# M5531 register map
File version: 1.0
Registers are 32-bit, read-write, reset 0x0 unless marked. A register's access mark holds for its fields unless they carry their own. Offsets are from the block's base; [hi:lo] are bit positions; 'fields as' and 'values as' point back to an identical list.

## HSUSBD (part 2 of 2) — USBD Register Map
Base 0x40205000
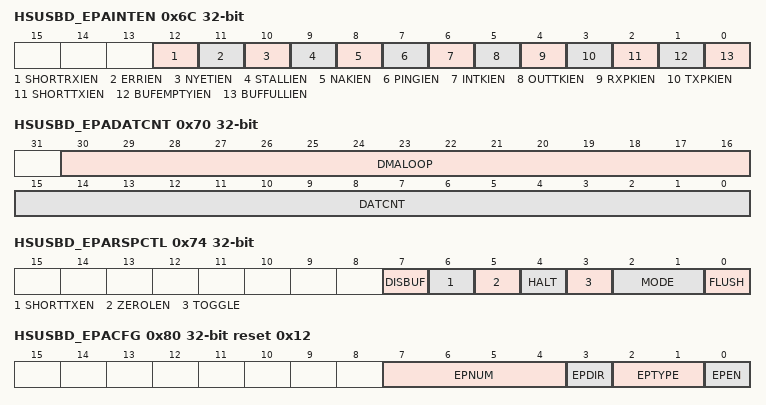
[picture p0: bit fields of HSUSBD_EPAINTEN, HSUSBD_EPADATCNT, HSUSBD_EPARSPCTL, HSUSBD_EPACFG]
0x6C HSUSBD_EPAINTEN — Endpoint A Interrupt Enable Control Register
  [12] SHORTRXIEN — Bulk Out Short Packet Received Interrupt Enable Bit. When set, this bit enables a local interrupt to be set whenever bulk out short packet occurs on the bus for this endpoint.
    0=Bulk out interrupt Disabled; 1=Bulk out interrupt Enabled
  [11] ERRIEN — ERR Sent Interrupt Enable Bit. When set, this bit enables a local interrupt to be set whenever ERR condition occurs on the bus for this endpoint.
    0=Error event interrupt Disabled; 1=Error event interrupt Enabled
  [10] NYETIEN — NYET Sent Interrupt Enable Bit. When set, this bit enables a local interrupt to be set whenever NYET condition occurs on the bus for this endpoint.
    0=NYET condition interrupt Disabled; 1=NYET condition interrupt Enabled
  [9] STALLIEN — USB STALL Sent Interrupt Enable Bit. When set, this bit enables a local interrupt to be set when a stall token is sent to the host.
    0=STALL token interrupt Disabled; 1=STALL token interrupt Enabled
  [8] NAKIEN — USB NAK Sent Interrupt Enable Bit. When set, this bit enables a local interrupt to be set when a NAK token is sent to the host.
    0=NAK token interrupt Disabled; 1=NAK token interrupt Enabled
  [7] PINGIEN — PING Token Interrupt Enable Bit. When set, this bit enables a local interrupt to be set when a PING token has been received from the host.
    0=PING token interrupt Disabled; 1=PING token interrupt Enabled
  [6] INTKIEN — Data IN Token Interrupt Enable Bit. When set, this bit enables a local interrupt to be set when a Data IN token has been received from the host.
    0=Data IN token interrupt Disabled; 1=Data IN token interrupt Enabled
  [5] OUTTKIEN — Data OUT Token Interrupt Enable Bit. When set, this bit enables a local interrupt to be set when a Data OUT token has been received from the host.
    0=Data OUT token interrupt Disabled; 1=Data OUT token interrupt Enabled
  [4] RXPKIEN — Data Packet Received Interrupt Enable Bit. When set, this bit enables a local interrupt to be set when a data packet has been received from the host.
    0=Data packet has been received from the host interrupt Disabled; 1=Data packet has been received from the host interrupt Enabled
  [3] TXPKIEN — Data Packet Transmitted Interrupt Enable Bit. When set, this bit enables a local interrupt to be set when a data packet has been transmitted to the host.
    0=Data packet has been transmitted to the host interrupt Disabled; 1=Data packet has been transmitted to the host interrupt Enabled
  [2] SHORTTXIEN — Short Packet Transferred Interrupt Enable Bit. When set, this bit enables a local interrupt to be set when a short data packet has been transferred to/from the host.
    0=Short data packet interrupt Disabled; 1=Short data packet interrupt Enabled
  [1] BUFEMPTYIEN — Buffer Empty Interrupt Enable Bit. When set, this bit enables a local interrupt to be set when a buffer empty condition is detected on the bus.
    0=Buffer empty interrupt Disabled; 1=Buffer empty interrupt Enabled
  [0] BUFFULLIEN — Buffer Full Interrupt Enable Bit. When set, this bit enables a local interrupt to be set when a buffer full condition is detected on the bus.
    0=Buffer full interrupt Disabled; 1=Buffer full interrupt Enabled
0x70 HSUSBD_EPADATCNT ro — Endpoint A Data Available Count Register
  [30:16] DMALOOP — DMA Loop. This register is the remaining DMA loop to complete. Each loop means 32-byte transfer.
  [15:0] DATCNT — Data Count. For an IN endpoint (EPDIR (HSUSBD_EPxCFG[3] is high.), this register returns the number of valid bytes in the IN endpoint packet buffer. For an OUT endpoint (EPDIR (HSUSBD_EPxCFG[3] is low.), this register returns the number of received valid bytes in the Host OUT transfer.
0x74 HSUSBD_EPARSPCTL — Endpoint A Response Control Register
  [7] DISBUF — Buffer Disable Bit. This bit is used to receive unknown size OUT short packet. The received packet size is reference HSUSBD_EPxDATCNT register.
    0=Buffer not disabled when Bulk-OUT short packet is received; 1=Buffer disabled when Bulk-OUT short packet is received
  [6] SHORTTXEN — Short Packet Transfer Enable. This bit is applicable only in case of Auto-Validate Method. This bit is set to validate any remaining data in the buffer which is not equal to the MPS of the endpoint, and happens to be the last transfer. This bit gets cleared once the data packet is sent.
    0=Not validate any remaining data in the buffer which is not equal to the MPS of the endpoint; 1=Validate any remaining data in the buffer which is not equal to the MPS of the endpoint
  [5] ZEROLEN — Zero Length. This bit is used to send a zero-length packet response to an IN-token. When this bit is set, a zero packet is sent to the host on reception of an IN-token. This bit gets cleared once the zero length data packet is sent.
    0=A zero packet is not sent to the host on reception of an IN-token; 1=A zero packet is sent to the host on reception of an IN-token
  [4] HALT — Endpoint Halt. This bit is used to send a STALL handshake as response to the token from the host. When an Endpoint Set Feature (ep_halt) is detected by the local CPU, it must write a '1' to this bit.
    0=Not send a STALL handshake as response to the token from the host; 1=Send a STALL handshake as response to the token from the host
  [3] TOGGLE — Endpoint Toggle. This bit is used to clear the endpoint data toggle bit. Reading this bit returns the current state of the endpoint data toggle bit. The local CPU may use this bit to initialize the end-point's toggle in case of reception of a Set Interface request or a Clear Feature (ep_halt) request from the host. Only when toggle bit is '1', this bit can be written into the inversed write data bit[3].
    0=Not clear the endpoint data toggle bit; 1=Clear the endpoint data toggle bit
  [2:1] MODE — Mode Control. The two bits decide the operation mode of the in-endpoint. These bits are not valid for an out-endpoint. The auto validate mode will be activated when the reserved mode is selected.
    0=Auto-Validate Mode; 1=Manual-Validate Mode; 2=Fly Mode
  [0] FLUSH — Buffer Flush. Writing 1 to this bit causes the packet buffer to be flushed and the corresponding EP_AVAIL register to be cleared. This bit is self-clearing. This bit should always be written after a configuration event.
    0=The packet buffer is not flushed; 1=The packet buffer is flushed by user
0x78 HSUSBD_EPAMPS — Endpoint A Maximum Packet Size Register
  [10:0] EPMPS — Endpoint Maximum Packet Size. This field determines the Maximum Packet Size of the Endpoint.
0x7C HSUSBD_EPATXCNT — Endpoint A Transfer Count Register
  [10:0] TXCNT — Endpoint Transfer Count. For IN endpoints, this field determines the total number of bytes to be sent to the host in case of manual validation method. For OUT endpoints, this field has no effect.
0x80 HSUSBD_EPACFG reset 0x12 — Endpoint A Configuration Register
  [7:4] EPNUM — Endpoint Number. This field selects the number of the endpoint. Valid numbers 1 to 15. Note: Do not support two endpoints have same endpoint number.
  [3] EPDIR — Endpoint Direction. Note: A maximum of one OUT and IN endpoint is allowed for each endpoint number.
    0=out-endpoint (Host OUT to Device); 1=in-endpoint (Host IN to Device)
  [2:1] EPTYPE — Endpoint Type. This field selects the type of this endpoint. Endpoint 0 is forced to a Control type.
    1=Bulk; 2=Interrupt; 3=Isochronous
  [0] EPEN — Endpoint Valid. When set, this bit enables this endpoint. This bit has no effect on Endpoint 0, which is always enabled.
    0=The endpoint Disabled; 1=The endpoint Enabled
0x84 HSUSBD_EPABUFSTART — Endpoint A RAM Start Address Register
  [13:0] SADDR — Endpoint Start Address. This is the start-address of the RAM space allocated for the endpoint A~R.
0x88 HSUSBD_EPABUFEND — Endpoint A RAM End Address Register
  [13:0] EADDR — Endpoint End Address. This is the end-address of the RAM space allocated for the endpoint A~R.
0x8C HSUSBD_EPBDAT — Endpoint B Data Register
  [31:0] EPDAT — Endpoint A~R Data Register. Endpoint A~R data buffer for the buffer transaction (read or write). Note: Only word or byte access are supported.
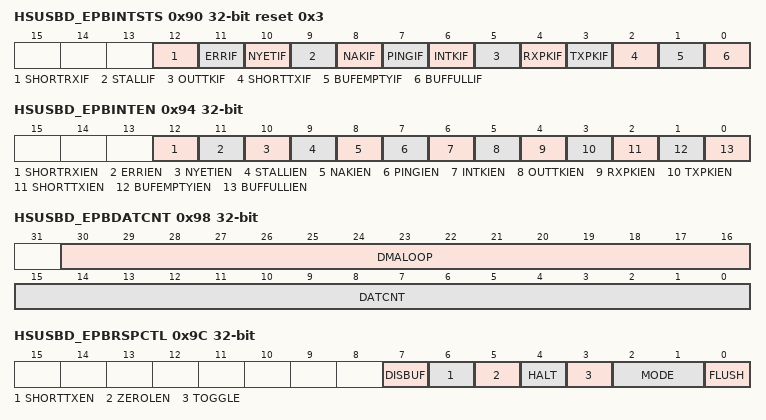
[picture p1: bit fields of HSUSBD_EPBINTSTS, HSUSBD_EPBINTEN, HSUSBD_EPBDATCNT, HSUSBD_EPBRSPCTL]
0x90 HSUSBD_EPBINTSTS reset 0x3 — Endpoint B Interrupt Status Register
  [12] SHORTRXIF — Bulk Out Short Packet Received Interrupt. Note: Write 1 to clear this bit to 0.
    0=No bulk out short packet is received; 1=Received bulk out short packet (including zero length packet)
  [11] ERRIF — ERR Sent Interrupt. Note: Write 1 to clear this bit to 0.
    0=No any error in the transaction; 1=There occurs any error in the transaction
  [10] NYETIF — NYET Sent Interrupt. Note: Write 1 to clear this bit to 0.
    0=The space available in the RAM is sufficient to accommodate the next on coming data packet; 1=The space available in the RAM is not sufficient to accommodate the next on coming data packet
  [9] STALLIF — USB STALL Sent Interrupt. Note: Write 1 to clear this bit to 0.
    0=The last USB packet could be accepted or provided because the endpoint was stalled, and was acknowledged with a STALL; 1=The last USB packet could not be accepted or provided because the endpoint was stalled, and was acknowledged with a STALL
  [8] NAKIF — USB NAK Sent Interrupt. Note: Write 1 to clear this bit to 0.
    0=The last USB IN packet could be provided, and was acknowledged with an ACK; 1=The last USB IN packet could not be provided, and was acknowledged with a NAK
  [7] PINGIF — PING Token Interrupt. Note: Write 1 to clear this bit to 0.
    0=A Data PING token has not been received from the host; 1=A Data PING token has been received from the host
  [6] INTKIF — Data IN Token Interrupt. Note: Write 1 to clear this bit to 0.
    0=Not Data IN token has been received from the host; 1=A Data IN token has been received from the host
  [5] OUTTKIF — Data OUT Token Interrupt. Note: Write 1 to clear this bit to 0.
    0=A Data OUT token has not been received from the host; 1=A Data OUT token has been received from the host. This bit also set by PING token (in high-speed only)
  [4] RXPKIF — Data Packet Received Interrupt. Note: Write 1 to clear this bit to 0.
    0=No data packet is received from the host by the endpoint; 1=A data packet is received from the host by the endpoint
  [3] TXPKIF — Data Packet Transmitted Interrupt. Note: Write 1 to clear this bit to 0.
    0=Not a data packet is transmitted from the endpoint to the host; 1=A data packet is transmitted from the endpoint to the host
  [2] SHORTTXIF — Short Packet Transferred Interrupt. Note: Write 1 to clear this bit to 0.
    0=The length of the last packet was not less than the Maximum Packet Size (EPMPS); 1=The length of the last packet was less than the Maximum Packet Size (EPMPS)
  [1] BUFEMPTYIF — Buffer Empty Interrupt. For an IN endpoint, a buffer is available to the local side for writing up to FIFO full of bytes. Note: This bit is read-only.
    0=The endpoint buffer is not empty. The currently selected buffer has not a count of 0; 1=The endpoint buffer is empty. The currently selected buffer has a count of 0, or no buffer is available on the local side (nothing to read)
  [0] BUFFULLIF — Buffer Full Interrupt. For an IN endpoint, the currently selected buffer is full, or no buffer is available to the local side for writing (no space to write). For an OUT endpoint, there is a buffer available on the local side, and there are FIFO full of bytes available to be read (entire packet is available for reading). Note: This bit is read-only.
    0=The endpoint packet buffer is not full; 1=The endpoint packet buffer is full
0x94 HSUSBD_EPBINTEN — Endpoint B Interrupt Enable Control Register
  fields as HSUSBD_EPAINTEN
0x98 HSUSBD_EPBDATCNT ro — Endpoint B Data Available Count Register
  fields as HSUSBD_EPADATCNT
0x9C HSUSBD_EPBRSPCTL — Endpoint B Response Control Register
  fields as HSUSBD_EPARSPCTL
0xA0 HSUSBD_EPBMPS — Endpoint B Maximum Packet Size Register
  fields as HSUSBD_EPAMPS
0xA4 HSUSBD_EPBTXCNT — Endpoint B Transfer Count Register
  fields as HSUSBD_EPATXCNT
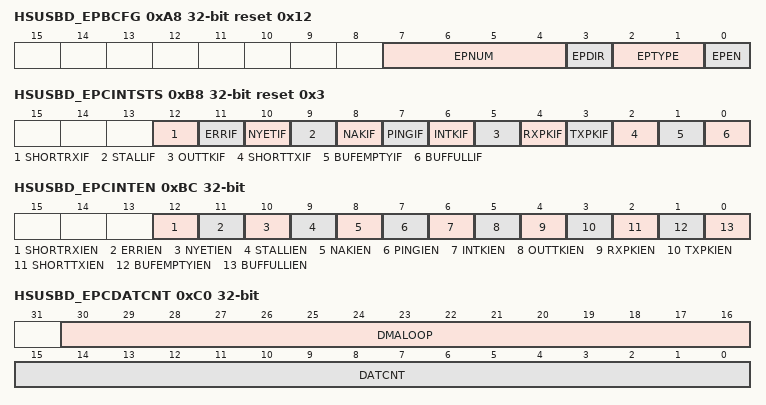
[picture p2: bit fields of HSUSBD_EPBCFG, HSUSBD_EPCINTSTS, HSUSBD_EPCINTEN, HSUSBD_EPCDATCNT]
0xA8 HSUSBD_EPBCFG reset 0x12 — Endpoint B Configuration Register
  fields as HSUSBD_EPACFG
0xAC HSUSBD_EPBBUFSTART — Endpoint B RAM Start Address Register
  fields as HSUSBD_EPABUFSTART
0xB0 HSUSBD_EPBBUFEND — Endpoint B RAM End Address Register
  fields as HSUSBD_EPABUFEND
0xB4 HSUSBD_EPCDAT — Endpoint C Data Register
  fields as HSUSBD_EPBDAT
0xB8 HSUSBD_EPCINTSTS reset 0x3 — Endpoint C Interrupt Status Register
  fields as HSUSBD_EPBINTSTS
0xBC HSUSBD_EPCINTEN — Endpoint C Interrupt Enable Control Register
  fields as HSUSBD_EPAINTEN
0xC0 HSUSBD_EPCDATCNT ro — Endpoint C Data Available Count Register
  fields as HSUSBD_EPADATCNT
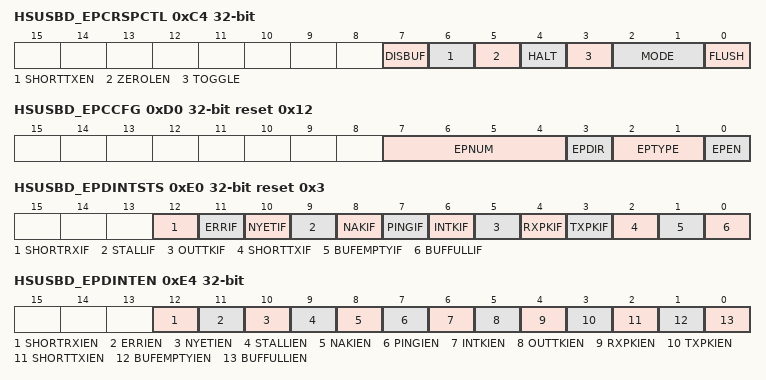
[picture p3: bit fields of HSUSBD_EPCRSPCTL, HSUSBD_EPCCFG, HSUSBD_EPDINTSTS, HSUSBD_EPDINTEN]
0xC4 HSUSBD_EPCRSPCTL — Endpoint C Response Control Register
  fields as HSUSBD_EPARSPCTL
0xC8 HSUSBD_EPCMPS — Endpoint C Maximum Packet Size Register
  fields as HSUSBD_EPAMPS
0xCC HSUSBD_EPCTXCNT — Endpoint C Transfer Count Register
  fields as HSUSBD_EPATXCNT
0xD0 HSUSBD_EPCCFG reset 0x12 — Endpoint C Configuration Register
  fields as HSUSBD_EPACFG
0xD4 HSUSBD_EPCBUFSTART — Endpoint C RAM Start Address Register
  fields as HSUSBD_EPABUFSTART
0xD8 HSUSBD_EPCBUFEND — Endpoint C RAM End Address Register
  fields as HSUSBD_EPABUFEND
0xDC HSUSBD_EPDDAT — Endpoint D Data Register
  fields as HSUSBD_EPBDAT
0xE0 HSUSBD_EPDINTSTS reset 0x3 — Endpoint D Interrupt Status Register
  fields as HSUSBD_EPBINTSTS
0xE4 HSUSBD_EPDINTEN — Endpoint D Interrupt Enable Control Register
  fields as HSUSBD_EPAINTEN
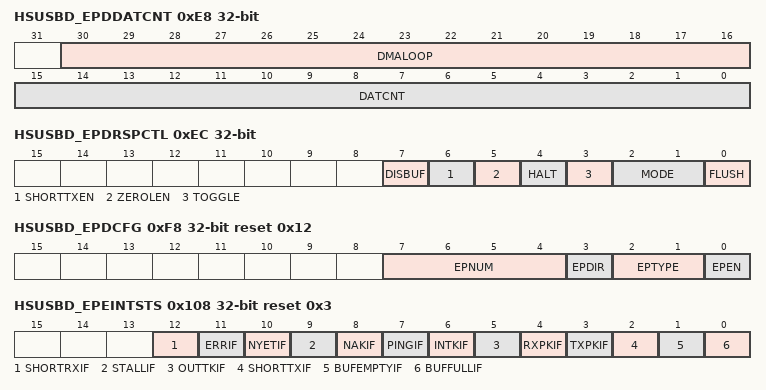
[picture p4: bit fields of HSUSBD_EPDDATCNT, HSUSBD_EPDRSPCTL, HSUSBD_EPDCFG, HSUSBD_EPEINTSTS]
0xE8 HSUSBD_EPDDATCNT ro — Endpoint D Data Available Count Register
  fields as HSUSBD_EPADATCNT
0xEC HSUSBD_EPDRSPCTL — Endpoint D Response Control Register
  fields as HSUSBD_EPARSPCTL
0xF0 HSUSBD_EPDMPS — Endpoint D Maximum Packet Size Register
  fields as HSUSBD_EPAMPS
0xF4 HSUSBD_EPDTXCNT — Endpoint D Transfer Count Register
  fields as HSUSBD_EPATXCNT
0xF8 HSUSBD_EPDCFG reset 0x12 — Endpoint D Configuration Register
  fields as HSUSBD_EPACFG
0xFC HSUSBD_EPDBUFSTART — Endpoint D RAM Start Address Register
  fields as HSUSBD_EPABUFSTART
0x100 HSUSBD_EPDBUFEND — Endpoint D RAM End Address Register
  fields as HSUSBD_EPABUFEND
0x104 HSUSBD_EPEDAT — Endpoint E Data Register
  fields as HSUSBD_EPBDAT
0x108 HSUSBD_EPEINTSTS reset 0x3 — Endpoint E Interrupt Status Register
  fields as HSUSBD_EPBINTSTS
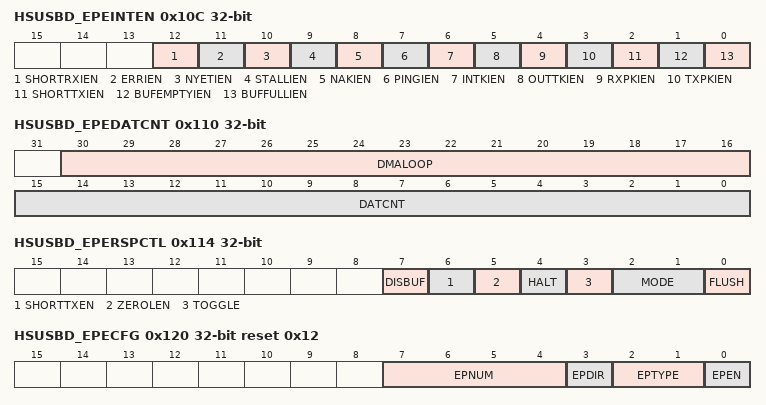
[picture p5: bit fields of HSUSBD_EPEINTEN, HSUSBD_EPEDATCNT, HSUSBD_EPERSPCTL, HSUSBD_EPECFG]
0x10C HSUSBD_EPEINTEN — Endpoint E Interrupt Enable Control Register
  fields as HSUSBD_EPAINTEN
0x110 HSUSBD_EPEDATCNT ro — Endpoint E Data Available Count Register
  fields as HSUSBD_EPADATCNT
0x114 HSUSBD_EPERSPCTL — Endpoint E Response Control Register
  fields as HSUSBD_EPARSPCTL
0x118 HSUSBD_EPEMPS — Endpoint E Maximum Packet Size Register
  fields as HSUSBD_EPAMPS
0x11C HSUSBD_EPETXCNT — Endpoint E Transfer Count Register
  fields as HSUSBD_EPATXCNT
0x120 HSUSBD_EPECFG reset 0x12 — Endpoint E Configuration Register
  fields as HSUSBD_EPACFG
0x124 HSUSBD_EPEBUFSTART — Endpoint E RAM Start Address Register
  fields as HSUSBD_EPABUFSTART
0x128 HSUSBD_EPEBUFEND — Endpoint E RAM End Address Register
  fields as HSUSBD_EPABUFEND
0x12C HSUSBD_EPFDAT — Endpoint F Data Register
  fields as HSUSBD_EPBDAT
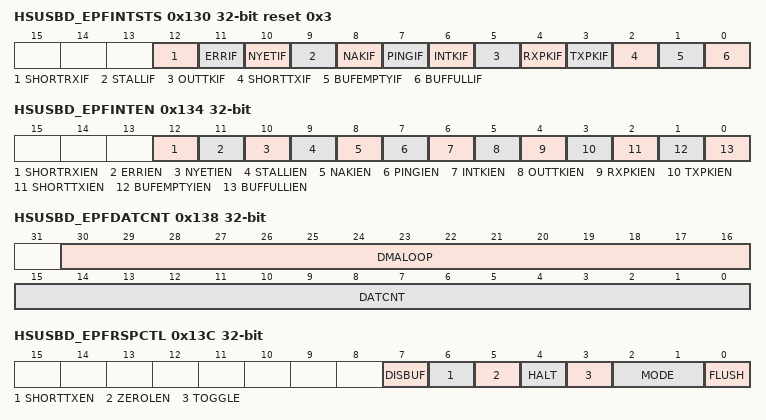
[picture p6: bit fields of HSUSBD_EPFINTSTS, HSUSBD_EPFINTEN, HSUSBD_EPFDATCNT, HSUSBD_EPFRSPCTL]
0x130 HSUSBD_EPFINTSTS reset 0x3 — Endpoint F Interrupt Status Register
  fields as HSUSBD_EPBINTSTS
0x134 HSUSBD_EPFINTEN — Endpoint F Interrupt Enable Control Register
  fields as HSUSBD_EPAINTEN
0x138 HSUSBD_EPFDATCNT ro — Endpoint F Data Available Count Register
  fields as HSUSBD_EPADATCNT
0x13C HSUSBD_EPFRSPCTL — Endpoint F Response Control Register
  fields as HSUSBD_EPARSPCTL
0x140 HSUSBD_EPFMPS — Endpoint F Maximum Packet Size Register
  fields as HSUSBD_EPAMPS
0x144 HSUSBD_EPFTXCNT — Endpoint F Transfer Count Register
  fields as HSUSBD_EPATXCNT
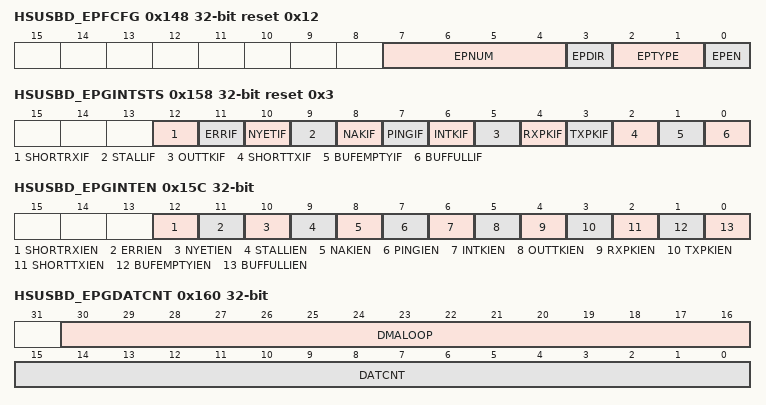
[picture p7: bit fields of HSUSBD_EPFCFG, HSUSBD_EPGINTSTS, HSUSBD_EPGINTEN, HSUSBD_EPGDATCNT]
0x148 HSUSBD_EPFCFG reset 0x12 — Endpoint F Configuration Register
  fields as HSUSBD_EPACFG
0x14C HSUSBD_EPFBUFSTART — Endpoint F RAM Start Address Register
  fields as HSUSBD_EPABUFSTART
0x150 HSUSBD_EPFBUFEND — Endpoint F RAM End Address Register
  fields as HSUSBD_EPABUFEND
0x154 HSUSBD_EPGDAT — Endpoint G Data Register
  fields as HSUSBD_EPBDAT
0x158 HSUSBD_EPGINTSTS reset 0x3 — Endpoint G Interrupt Status Register
  fields as HSUSBD_EPBINTSTS
0x15C HSUSBD_EPGINTEN — Endpoint G Interrupt Enable Control Register
  fields as HSUSBD_EPAINTEN
0x160 HSUSBD_EPGDATCNT ro — Endpoint G Data Available Count Register
  fields as HSUSBD_EPADATCNT
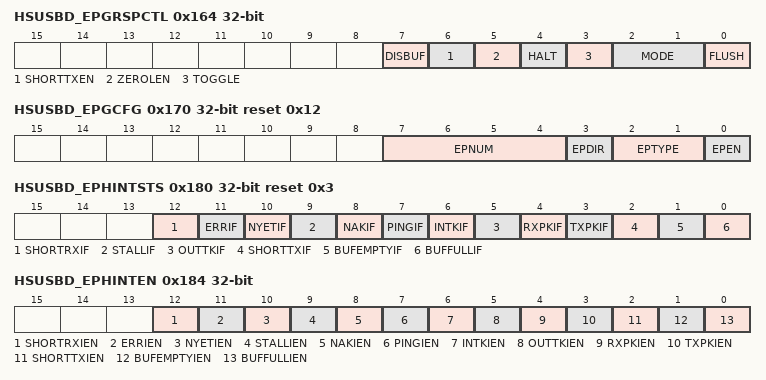
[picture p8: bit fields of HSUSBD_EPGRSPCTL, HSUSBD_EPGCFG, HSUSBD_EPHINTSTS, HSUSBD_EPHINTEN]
0x164 HSUSBD_EPGRSPCTL — Endpoint G Response Control Register
  fields as HSUSBD_EPARSPCTL
0x168 HSUSBD_EPGMPS — Endpoint G Maximum Packet Size Register
  fields as HSUSBD_EPAMPS
0x16C HSUSBD_EPGTXCNT — Endpoint G Transfer Count Register
  fields as HSUSBD_EPATXCNT
0x170 HSUSBD_EPGCFG reset 0x12 — Endpoint G Configuration Register
  fields as HSUSBD_EPACFG
0x174 HSUSBD_EPGBUFSTART — Endpoint G RAM Start Address Register
  fields as HSUSBD_EPABUFSTART
0x178 HSUSBD_EPGBUFEND — Endpoint G RAM End Address Register
  fields as HSUSBD_EPABUFEND
0x17C HSUSBD_EPHDAT — Endpoint H Data Register
  fields as HSUSBD_EPBDAT
0x180 HSUSBD_EPHINTSTS reset 0x3 — Endpoint H Interrupt Status Register
  fields as HSUSBD_EPBINTSTS
0x184 HSUSBD_EPHINTEN — Endpoint H Interrupt Enable Control Register
  fields as HSUSBD_EPAINTEN
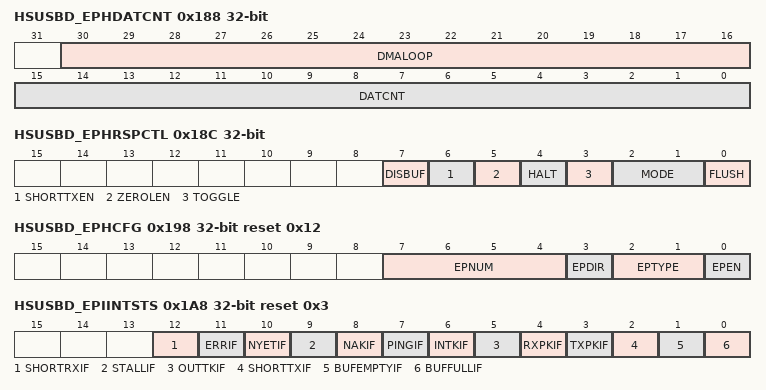
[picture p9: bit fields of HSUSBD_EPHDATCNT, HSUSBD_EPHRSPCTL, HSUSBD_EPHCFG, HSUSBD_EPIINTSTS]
0x188 HSUSBD_EPHDATCNT ro — Endpoint H Data Available Count Register
  fields as HSUSBD_EPADATCNT
0x18C HSUSBD_EPHRSPCTL — Endpoint H Response Control Register
  fields as HSUSBD_EPARSPCTL
0x190 HSUSBD_EPHMPS — Endpoint H Maximum Packet Size Register
  fields as HSUSBD_EPAMPS
0x194 HSUSBD_EPHTXCNT — Endpoint H Transfer Count Register
  fields as HSUSBD_EPATXCNT
0x198 HSUSBD_EPHCFG reset 0x12 — Endpoint H Configuration Register
  fields as HSUSBD_EPACFG
0x19C HSUSBD_EPHBUFSTART — Endpoint H RAM Start Address Register
  fields as HSUSBD_EPABUFSTART
0x1A0 HSUSBD_EPHBUFEND — Endpoint H RAM End Address Register
  fields as HSUSBD_EPABUFEND
0x1A4 HSUSBD_EPIDAT — Endpoint I Data Register
  fields as HSUSBD_EPBDAT
0x1A8 HSUSBD_EPIINTSTS reset 0x3 — Endpoint I Interrupt Status Register
  fields as HSUSBD_EPBINTSTS
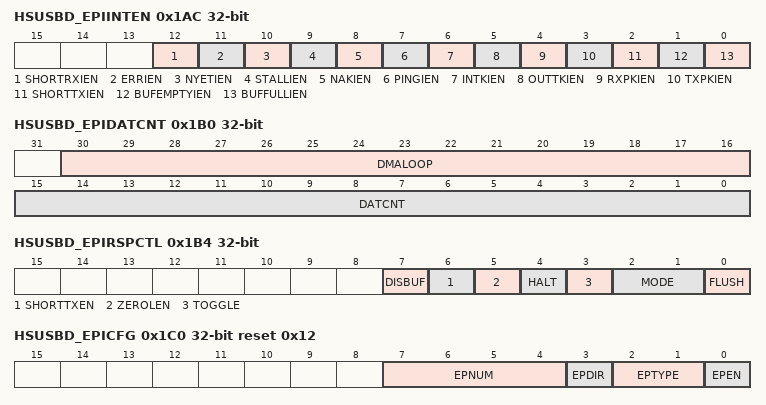
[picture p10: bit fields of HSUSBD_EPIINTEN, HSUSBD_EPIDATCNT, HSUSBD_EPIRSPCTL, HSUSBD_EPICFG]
0x1AC HSUSBD_EPIINTEN — Endpoint I Interrupt Enable Control Register
  fields as HSUSBD_EPAINTEN
0x1B0 HSUSBD_EPIDATCNT ro — Endpoint I Data Available Count Register
  fields as HSUSBD_EPADATCNT
0x1B4 HSUSBD_EPIRSPCTL — Endpoint I Response Control Register
  fields as HSUSBD_EPARSPCTL
0x1B8 HSUSBD_EPIMPS — Endpoint I Maximum Packet Size Register
  fields as HSUSBD_EPAMPS
0x1BC HSUSBD_EPITXCNT — Endpoint I Transfer Count Register
  fields as HSUSBD_EPATXCNT
0x1C0 HSUSBD_EPICFG reset 0x12 — Endpoint I Configuration Register
  fields as HSUSBD_EPACFG
0x1C4 HSUSBD_EPIBUFSTART — Endpoint I RAM Start Address Register
  fields as HSUSBD_EPABUFSTART
0x1C8 HSUSBD_EPIBUFEND — Endpoint I RAM End Address Register
  fields as HSUSBD_EPABUFEND
0x1CC HSUSBD_EPJDAT — Endpoint J Data Register
  fields as HSUSBD_EPBDAT
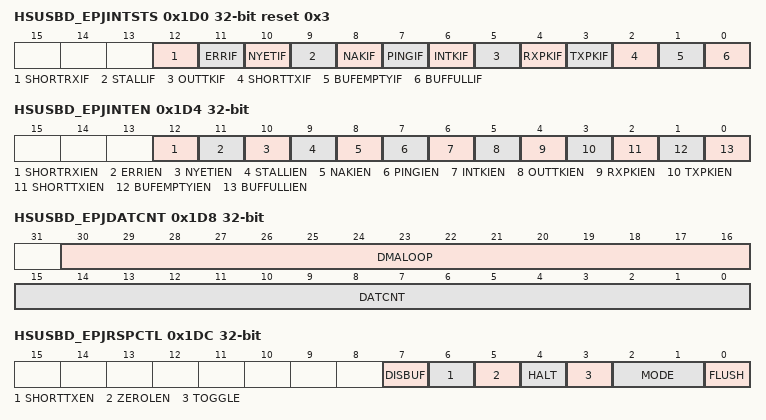
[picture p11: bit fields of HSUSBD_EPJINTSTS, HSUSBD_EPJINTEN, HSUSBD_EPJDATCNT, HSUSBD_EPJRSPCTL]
0x1D0 HSUSBD_EPJINTSTS reset 0x3 — Endpoint J Interrupt Status Register
  fields as HSUSBD_EPBINTSTS
0x1D4 HSUSBD_EPJINTEN — Endpoint J Interrupt Enable Control Register
  fields as HSUSBD_EPAINTEN
0x1D8 HSUSBD_EPJDATCNT ro — Endpoint J Data Available Count Register
  fields as HSUSBD_EPADATCNT
0x1DC HSUSBD_EPJRSPCTL — Endpoint J Response Control Register
  fields as HSUSBD_EPARSPCTL
0x1E0 HSUSBD_EPJMPS — Endpoint J Maximum Packet Size Register
  fields as HSUSBD_EPAMPS
0x1E4 HSUSBD_EPJTXCNT — Endpoint J Transfer Count Register
  fields as HSUSBD_EPATXCNT
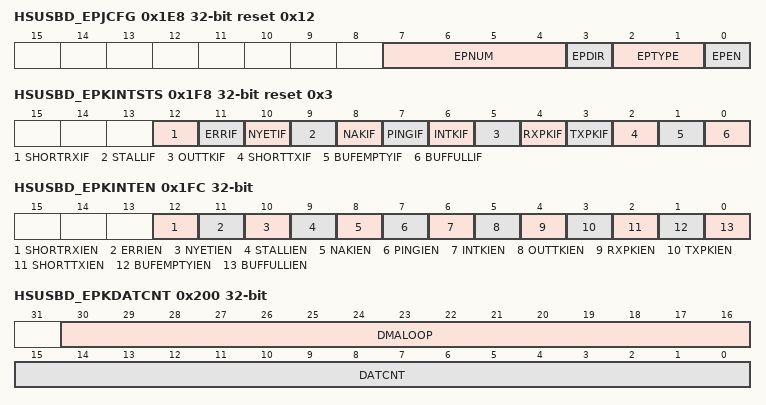
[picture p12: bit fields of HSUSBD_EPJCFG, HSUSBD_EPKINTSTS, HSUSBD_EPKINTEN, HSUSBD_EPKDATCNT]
0x1E8 HSUSBD_EPJCFG reset 0x12 — Endpoint J Configuration Register
  fields as HSUSBD_EPACFG
0x1EC HSUSBD_EPJBUFSTART — Endpoint J RAM Start Address Register
  fields as HSUSBD_EPABUFSTART
0x1F0 HSUSBD_EPJBUFEND — Endpoint J RAM End Address Register
  fields as HSUSBD_EPABUFEND
0x1F4 HSUSBD_EPKDAT — Endpoint K Data Register
  fields as HSUSBD_EPBDAT
0x1F8 HSUSBD_EPKINTSTS reset 0x3 — Endpoint K Interrupt Status Register
  fields as HSUSBD_EPBINTSTS
0x1FC HSUSBD_EPKINTEN — Endpoint K Interrupt Enable Control Register
  fields as HSUSBD_EPAINTEN
0x200 HSUSBD_EPKDATCNT ro — Endpoint K Data Available Count Register
  fields as HSUSBD_EPADATCNT
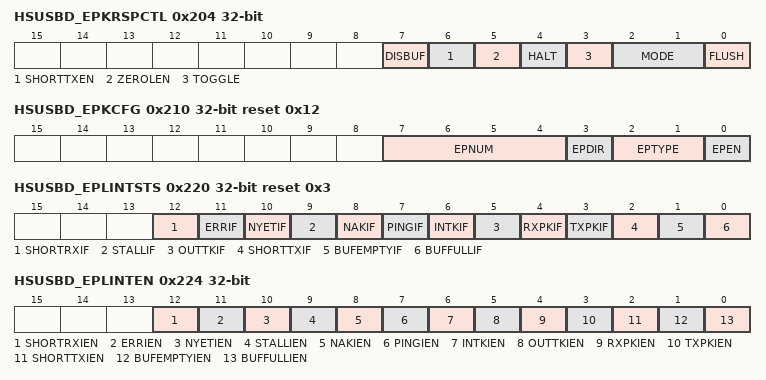
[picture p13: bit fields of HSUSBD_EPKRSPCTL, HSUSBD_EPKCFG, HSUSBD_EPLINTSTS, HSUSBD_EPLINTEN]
0x204 HSUSBD_EPKRSPCTL — Endpoint K Response Control Register
  fields as HSUSBD_EPARSPCTL
0x208 HSUSBD_EPKMPS — Endpoint K Maximum Packet Size Register
  fields as HSUSBD_EPAMPS
0x20C HSUSBD_EPKTXCNT — Endpoint K Transfer Count Register
  fields as HSUSBD_EPATXCNT
0x210 HSUSBD_EPKCFG reset 0x12 — Endpoint K Configuration Register
  fields as HSUSBD_EPACFG
0x214 HSUSBD_EPKBUFSTART — Endpoint K RAM Start Address Register
  fields as HSUSBD_EPABUFSTART
0x218 HSUSBD_EPKBUFEND — Endpoint K RAM End Address Register
  fields as HSUSBD_EPABUFEND
0x21C HSUSBD_EPLDAT — Endpoint L Data Register
  fields as HSUSBD_EPBDAT
0x220 HSUSBD_EPLINTSTS reset 0x3 — Endpoint L Interrupt Status Register
  fields as HSUSBD_EPBINTSTS
0x224 HSUSBD_EPLINTEN — Endpoint L Interrupt Enable Control Register
  fields as HSUSBD_EPAINTEN
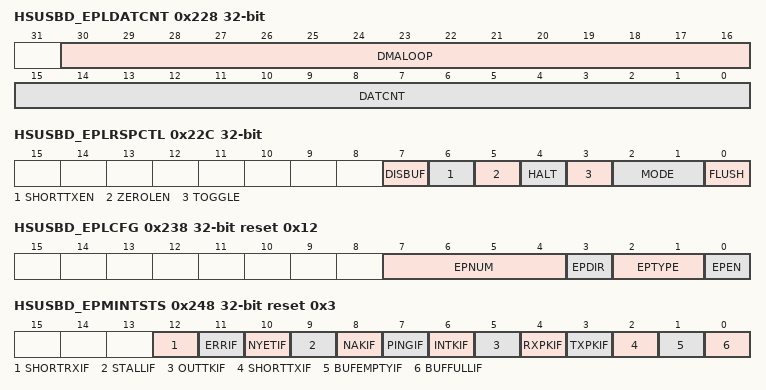
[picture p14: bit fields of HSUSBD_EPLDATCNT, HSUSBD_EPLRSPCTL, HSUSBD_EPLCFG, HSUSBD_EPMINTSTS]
0x228 HSUSBD_EPLDATCNT ro — Endpoint L Data Available Count Register
  fields as HSUSBD_EPADATCNT
0x22C HSUSBD_EPLRSPCTL — Endpoint L Response Control Register
  fields as HSUSBD_EPARSPCTL
0x230 HSUSBD_EPLMPS — Endpoint L Maximum Packet Size Register
  fields as HSUSBD_EPAMPS
0x234 HSUSBD_EPLTXCNT — Endpoint L Transfer Count Register
  fields as HSUSBD_EPATXCNT
0x238 HSUSBD_EPLCFG reset 0x12 — Endpoint L Configuration Register
  fields as HSUSBD_EPACFG
0x23C HSUSBD_EPLBUFSTART — Endpoint L RAM Start Address Register
  fields as HSUSBD_EPABUFSTART
0x240 HSUSBD_EPLBUFEND — Endpoint L RAM End Address Register
  fields as HSUSBD_EPABUFEND
0x244 HSUSBD_EPMDAT — Endpoint M Data Register
  fields as HSUSBD_EPBDAT
0x248 HSUSBD_EPMINTSTS reset 0x3 — Endpoint M Interrupt Status Register
  fields as HSUSBD_EPBINTSTS
0x24C HSUSBD_EPMINTEN — Endpoint M Interrupt Enable Control Register
  fields as HSUSBD_EPAINTEN
0x250 HSUSBD_EPMDATCNT ro — Endpoint M Data Available Count Register
  fields as HSUSBD_EPADATCNT
0x254 HSUSBD_EPMRSPCTL — Endpoint M Response Control Register
  fields as HSUSBD_EPARSPCTL
0x258 HSUSBD_EPMMPS — Endpoint M Maximum Packet Size Register
  fields as HSUSBD_EPAMPS
0x25C HSUSBD_EPMTXCNT — Endpoint M Transfer Count Register
  fields as HSUSBD_EPATXCNT
0x260 HSUSBD_EPMCFG reset 0x12 — Endpoint M Configuration Register
  fields as HSUSBD_EPACFG
0x264 HSUSBD_EPMBUFSTART — Endpoint M RAM Start Address Register
  fields as HSUSBD_EPABUFSTART
0x268 HSUSBD_EPMBUFEND — Endpoint M RAM End Address Register
  fields as HSUSBD_EPABUFEND
0x26C HSUSBD_EPNDAT — Endpoint N Data Register
  fields as HSUSBD_EPBDAT
0x270 HSUSBD_EPNINTSTS reset 0x3 — Endpoint N Interrupt Status Register
  fields as HSUSBD_EPBINTSTS
0x274 HSUSBD_EPNINTEN — Endpoint N Interrupt Enable Control Register
  fields as HSUSBD_EPAINTEN
0x278 HSUSBD_EPNDATCNT ro — Endpoint N Data Available Count Register
  fields as HSUSBD_EPADATCNT
0x27C HSUSBD_EPNRSPCTL — Endpoint N Response Control Register
  fields as HSUSBD_EPARSPCTL
0x280 HSUSBD_EPNMPS — Endpoint N Maximum Packet Size Register
  fields as HSUSBD_EPAMPS
0x284 HSUSBD_EPNTXCNT — Endpoint N Transfer Count Register
  fields as HSUSBD_EPATXCNT
0x288 HSUSBD_EPNCFG reset 0x12 — Endpoint N Configuration Register
  fields as HSUSBD_EPACFG
0x28C HSUSBD_EPNBUFSTART — Endpoint N RAM Start Address Register
  fields as HSUSBD_EPABUFSTART
0x290 HSUSBD_EPNBUFEND — Endpoint N RAM End Address Register
  fields as HSUSBD_EPABUFEND
0x294 HSUSBD_EPODAT — Endpoint O Data Register
  fields as HSUSBD_EPBDAT
0x298 HSUSBD_EPOINTSTS reset 0x3 — Endpoint O Interrupt Status Register
  fields as HSUSBD_EPBINTSTS
0x29C HSUSBD_EPOINTEN — Endpoint O Interrupt Enable Control Register
  fields as HSUSBD_EPAINTEN
0x2A0 HSUSBD_EPODATCNT ro — Endpoint O Data Available Count Register
  fields as HSUSBD_EPADATCNT
0x2A4 HSUSBD_EPORSPCTL — Endpoint O Response Control Register
  fields as HSUSBD_EPARSPCTL
0x2A8 HSUSBD_EPOMPS — Endpoint O Maximum Packet Size Register
  fields as HSUSBD_EPAMPS
0x2AC HSUSBD_EPOTXCNT — Endpoint O Transfer Count Register
  fields as HSUSBD_EPATXCNT
0x2B0 HSUSBD_EPOCFG reset 0x12 — Endpoint O Configuration Register
  fields as HSUSBD_EPACFG
0x2B4 HSUSBD_EPOBUFSTART — Endpoint O RAM Start Address Register
  fields as HSUSBD_EPABUFSTART
0x2B8 HSUSBD_EPOBUFEND — Endpoint O RAM End Address Register
  fields as HSUSBD_EPABUFEND
0x2BC HSUSBD_EPPDAT — Endpoint P Data Register
  fields as HSUSBD_EPBDAT
0x2C0 HSUSBD_EPPINTSTS reset 0x3 — Endpoint P Interrupt Status Register
  fields as HSUSBD_EPBINTSTS
0x2C4 HSUSBD_EPPINTEN — Endpoint P Interrupt Enable Control Register
  fields as HSUSBD_EPAINTEN
0x2C8 HSUSBD_EPPDATCNT ro — Endpoint P Data Available Count Register
  fields as HSUSBD_EPADATCNT
0x2CC HSUSBD_EPPRSPCTL — Endpoint P Response Control Register
  fields as HSUSBD_EPARSPCTL
0x2D0 HSUSBD_EPPMPS — Endpoint P Maximum Packet Size Register
  fields as HSUSBD_EPAMPS
0x2D4 HSUSBD_EPPTXCNT — Endpoint P Transfer Count Register
  fields as HSUSBD_EPATXCNT
0x2D8 HSUSBD_EPPCFG reset 0x12 — Endpoint P Configuration Register
  fields as HSUSBD_EPACFG
0x2DC HSUSBD_EPPBUFSTART — Endpoint P RAM Start Address Register
  fields as HSUSBD_EPABUFSTART
0x2E0 HSUSBD_EPPBUFEND — Endpoint P RAM End Address Register
  fields as HSUSBD_EPABUFEND
0x2E4 HSUSBD_EPQDAT — Endpoint Q Data Register
  fields as HSUSBD_EPBDAT
0x2E8 HSUSBD_EPQINTSTS reset 0x3 — Endpoint Q Interrupt Status Register
  fields as HSUSBD_EPBINTSTS
0x2EC HSUSBD_EPQINTEN — Endpoint Q Interrupt Enable Control Register
  fields as HSUSBD_EPAINTEN
0x2F0 HSUSBD_EPQDATCNT ro — Endpoint Q Data Available Count Register
  fields as HSUSBD_EPADATCNT
0x2F4 HSUSBD_EPQRSPCTL — Endpoint Q Response Control Register
  fields as HSUSBD_EPARSPCTL
0x2F8 HSUSBD_EPQMPS — Endpoint Q Maximum Packet Size Register
  fields as HSUSBD_EPAMPS
0x2FC HSUSBD_EPQTXCNT — Endpoint Q Transfer Count Register
  fields as HSUSBD_EPATXCNT
0x300 HSUSBD_EPQCFG reset 0x12 — Endpoint Q Configuration Register
  fields as HSUSBD_EPACFG
0x304 HSUSBD_EPQBUFSTART — Endpoint Q RAM Start Address Register
  fields as HSUSBD_EPABUFSTART
0x308 HSUSBD_EPQBUFEND — Endpoint Q RAM End Address Register
  fields as HSUSBD_EPABUFEND
0x30C HSUSBD_EPRDAT — Endpoint R Data Register
  fields as HSUSBD_EPBDAT
0x310 HSUSBD_EPRINTSTS reset 0x3 — Endpoint R Interrupt Status Register
  fields as HSUSBD_EPBINTSTS
0x314 HSUSBD_EPRINTEN — Endpoint R Interrupt Enable Control Register
  fields as HSUSBD_EPAINTEN
0x318 HSUSBD_EPRDATCNT ro — Endpoint R Data Available Count Register
  fields as HSUSBD_EPADATCNT
0x31C HSUSBD_EPRRSPCTL — Endpoint R Response Control Register
  fields as HSUSBD_EPARSPCTL
0x320 HSUSBD_EPRMPS — Endpoint R Maximum Packet Size Register
  fields as HSUSBD_EPAMPS
0x324 HSUSBD_EPRTXCNT — Endpoint R Transfer Count Register
  fields as HSUSBD_EPATXCNT
0x328 HSUSBD_EPRCFG reset 0x12 — Endpoint R Configuration Register
  fields as HSUSBD_EPACFG
0x32C HSUSBD_EPRBUFSTART — Endpoint R RAM Start Address Register
  fields as HSUSBD_EPABUFSTART
0x330 HSUSBD_EPRBUFEND — Endpoint R RAM End Address Register
  fields as HSUSBD_EPABUFEND
0x6F8 HSUSBD_BCDC — Battery Charge Detect Control Register
  [31] BCDIF — Battery Charge Detect Interrupt Status. It supports VBUSOK and DCD interrupt status. Note: Write 1 to clear this bit to 0.
    0=BCD event did not occur; 1=BCD event occurred
  [30] BCDIEN — Battery Charge Detect Interrupt Enable Bit
    0=BCD Interrupt Disabled; 1=BCD Interrupt Enabled
  [5] USP — USB Special Port (Read Only)
    0=USB support port; 1=Special port. (PS/2 or proprietary charger)
  [4] DETSTS — Detect Status (Read Only)
    0=VBUS is less than threshold voltage. Data pin not contacted. SDP port or not USB support port. If it is not USB support port, USP is 1. CDP; 1=VBUS is greater than threshold voltage. Data pin contacted. DCP or CDP. DCP
  [3:1] DETMOD — Detect Mode
    0=Idle, nothing to detect; 1=VBUS detect, detect USB VBUS whether great than threshold voltage; 2=Data contact detect (DCD), detect data pin contact status; 3=Primary detect (PD), distinguish between (SDP or USP) and (CDP or DCP); 4=Secondary detect (SD), distinguish between CDP and DCP
  [0] BCDEN — Battery Charge Detect Enable Bit. Enable battery charge detect, select DETMOD and then observer DETSTS to decide contact port.
    0=Normal operation; 1=Battery charge detect operation
0x6FC HSUSBD_LPMCSR — LPM Control and Status Register
  [14] LPMSENDNYET — LPM Send NYET Response
    0=Not send a NYET handshake as response to the LPM token; 1=Send a NYET handshake as response to the LPM token
  [13] LPMSLEEPEN — LPM Sleep Function Enable Bit
    0=The LPM sleep function Disabled; 1=The LPM sleep function Enabled
  [12] LPMEN — LPM Function Enable Bit
    0=The LPM function Disabled; 1=The LPM function Enabled
  [10:0] bmAttributes — The LPM Token bmAttributes Field Definition (Read Only). Bit 10-9 (Reserved). Bit 8 (bRemoteWake). Bit 7-4 (HIRD). Bit 3-0 (bLinkState):
    1=L1 (Sleep)
0x700 HSUSBD_DMAADDR — AHB DMA Address Register
  [31:0] DMAADDR — DMAADDR. The register specifies the address from which the DMA has to read / write. The address must WORD (32-bit) aligned.
0x704 HSUSBD_PHYCTL — USB PHY Control Register
  [31] VBUSDET — VBUS Status
    0=The VBUS is not detected yet; 1=The VBUS is detected
  [27] PHYCLKSTB — PHY Clock Stable Flag
    0=The PHY clock is not stable for USB device usage; 1=The PHY clock is stable for USB device usage
  [26] STALLREVERT — Stall Revert Write Pointer Enable Bit
    0=The Stall revert write pointer function Disabled; 1=The Stall revert write pointer function Enabled
  [25] LINESTATEWKEN — Line State Wake-up Enable Bit
    0=The Line State wake-up function Disabled; 1=The Line State wake-up function Enabled
  [24] VBUSWKEN — VBUS Wake-up Enable Bit
    0=The wake-up function Disabled; 1=The wake-up function Enabled
  [9] PHYEN — PHY Suspend Enable Bit
    0=The USB PHY is suspend; 1=The USB PHY is not suspend
  [8] DPPUEN — DP Pull-up Enable Bit
    0=Pull-up resistor on D+ Disabled; 1=Pull-up resistor on D+ Enabled
